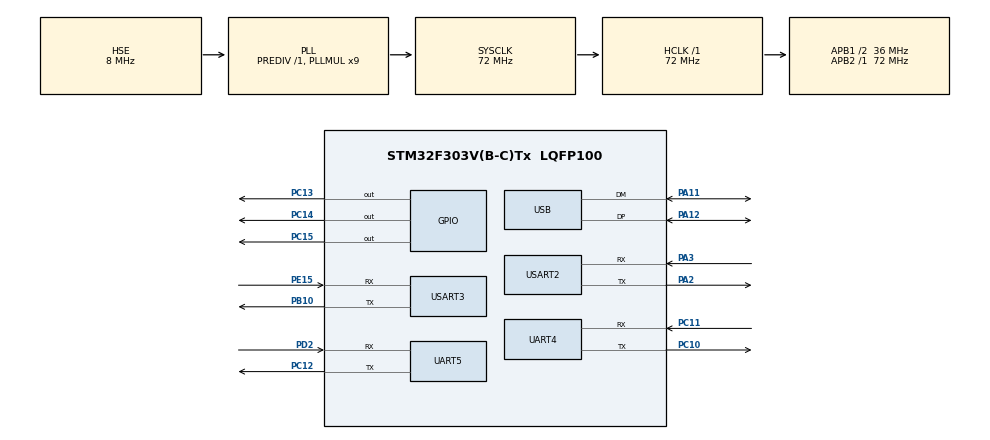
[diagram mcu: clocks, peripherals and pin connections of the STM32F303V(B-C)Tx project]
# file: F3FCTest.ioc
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Mcu.Family=STM32F3
Mcu.Name=STM32F303V(B-C)Tx
Mcu.Package=LQFP100
NVIC.PriorityGroup=NVIC_PRIORITYGROUP_4
PA11.Mode=Device
PA11.Signal=USB_DM
PA12.Mode=Device
PA12.Signal=USB_DP
PA13.Mode=Serial-Wire
PA13.Signal=SYS_JTMS-SWDIO
PA14.Mode=Serial-Wire
PA14.Signal=SYS_JTCK-SWCLK
PA2.Mode=Asynchronous
PA2.Signal=USART2_TX
PA3.Mode=Asynchronous
PA3.Signal=USART2_RX
PB10.Mode=Asynchronous
PB10.Signal=USART3_TX
PC10.Mode=Asynchronous
PC10.Signal=UART4_TX
PC11.Mode=Asynchronous
PC11.Signal=UART4_RX
PC12.Mode=Asynchronous
PC12.Signal=UART5_TX
PC13.Signal=GPIO_Output
PC14-OSC32_IN.Signal=GPIO_Output
PC15-OSC32_OUT.Signal=GPIO_Output
PD2.Mode=Asynchronous
PD2.Signal=UART5_RX
PE15.Mode=Asynchronous
PE15.Signal=USART3_RX
PF0-OSC_IN.Mode=HSE-External-Oscillator
PF0-OSC_IN.Signal=RCC_OSC_IN
PF1-OSC_OUT.Mode=HSE-External-Oscillator
PF1-OSC_OUT.Signal=RCC_OSC_OUT
ProjectManager.TargetToolchain=SW4STM32
RCC.AHBFreq_Value=72000000
RCC.APB1CLKDivider=RCC_HCLK_DIV2
RCC.APB1Freq_Value=36000000
RCC.APB1TimFreq_Value=72000000
RCC.APB2Freq_Value=72000000
RCC.APB2TimFreq_Value=72000000
RCC.CortexFreq_Value=72000000
RCC.HCLKFreq_Value=72000000
RCC.HSE_VALUE=8000000
RCC.HSIState=RCC_HSI_ON
RCC.HSI_VALUE=8000000
RCC.LSE_VALUE=32768
RCC.PLLMUL=RCC_PLL_MUL9
RCC.PRESCALERUSB=RCC_USBPLLCLK_DIV1_5
RCC.SYSCLKFreq_VALUE=72000000
RCC.SYSCLKSourceVirtual=RCC_SYSCLKSOURCE_PLLCLK
RCC.USBFreq_Value=48000000
board=F3FCTest

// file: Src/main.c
/**
  ******************************************************************************
  * File Name          : main.c
  * Description        : Main program body
  ******************************************************************************
  *
  * COPYRIGHT(c) 2015 STMicroelectronics
  *
  * Redistribution and use in source and binary forms, with or without modification,
  * are permitted provided that the following conditions are met:
  *   1. Redistributions of source code must retain the above copyright notice,
  *      this list of conditions and the following disclaimer.
  *   2. Redistributions in binary form must reproduce the above copyright notice,
  *      this list of conditions and the following disclaimer in the documentation
  *      and/or other materials provided with the distribution.
  *   3. Neither the name of STMicroelectronics nor the names of its contributors
  *      may be used to endorse or promote products derived from this software
  *      without specific prior written permission.
  *
  * THIS SOFTWARE IS PROVIDED BY THE COPYRIGHT HOLDERS AND CONTRIBUTORS "AS IS"
  * AND ANY EXPRESS OR IMPLIED WARRANTIES, INCLUDING, BUT NOT LIMITED TO, THE
  * IMPLIED WARRANTIES OF MERCHANTABILITY AND FITNESS FOR A PARTICULAR PURPOSE ARE
  * DISCLAIMED. IN NO EVENT SHALL THE COPYRIGHT HOLDER OR CONTRIBUTORS BE LIABLE
  * FOR ANY DIRECT, INDIRECT, INCIDENTAL, SPECIAL, EXEMPLARY, OR CONSEQUENTIAL
  * DAMAGES (INCLUDING, BUT NOT LIMITED TO, PROCUREMENT OF SUBSTITUTE GOODS OR
  * SERVICES; LOSS OF USE, DATA, OR PROFITS; OR BUSINESS INTERRUPTION) HOWEVER
  * CAUSED AND ON ANY THEORY OF LIABILITY, WHETHER IN CONTRACT, STRICT LIABILITY,
  * OR TORT (INCLUDING NEGLIGENCE OR OTHERWISE) ARISING IN ANY WAY OUT OF THE USE
  * OF THIS SOFTWARE, EVEN IF ADVISED OF THE POSSIBILITY OF SUCH DAMAGE.
  *
  ******************************************************************************
  */
#include "stm32f3xx_hal.h"

UART_HandleTypeDef huart4;
UART_HandleTypeDef huart5;
UART_HandleTypeDef huart2;
UART_HandleTypeDef huart3;

PCD_HandleTypeDef hpcd_USB_FS;

/* USER CODE BEGIN PV */
/* Private variables ---------------------------------------------------------*/

/* USER CODE END PV */

void SystemClock_Config(void);
static void MX_GPIO_Init(void);
static void MX_UART4_Init(void);
static void MX_UART5_Init(void);
static void MX_USART2_UART_Init(void);
static void MX_USART3_UART_Init(void);
static void MX_USB_PCD_Init(void);

/* USER CODE BEGIN PFP */
/* Private function prototypes -----------------------------------------------*/

/* USER CODE END PFP */

int main(void)
{

  /* MCU Configuration----------------------------------------------------------*/

  /* Reset of all peripherals, Initializes the Flash interface and the Systick. */
  HAL_Init();

  /* Configure the system clock */
  SystemClock_Config();

  /* Initialize all configured peripherals */
  MX_GPIO_Init();
  MX_UART4_Init();
  MX_UART5_Init();
  MX_USART2_UART_Init();
  MX_USART3_UART_Init();
  MX_USB_PCD_Init();

  /* USER CODE BEGIN 2 */
  long i = 0;
  /* USER CODE END 2 */

  /* Infinite loop */
  /* USER CODE BEGIN WHILE */
  while (1)
  {
    HAL_GPIO_TogglePin(GPIOC, GPIO_PIN_13);
    HAL_GPIO_TogglePin(GPIOC, GPIO_PIN_14);
    HAL_GPIO_TogglePin(GPIOC, GPIO_PIN_15);
    for(i = 0; i < 50000; i++);
  /* USER CODE END WHILE */

  }

}

/** System Clock Configuration
*/
void SystemClock_Config(void)
{

  RCC_OscInitTypeDef RCC_OscInitStruct;
  RCC_ClkInitTypeDef RCC_ClkInitStruct;
  RCC_PeriphCLKInitTypeDef PeriphClkInit;

  RCC_OscInitStruct.OscillatorType = RCC_OSCILLATORTYPE_HSE;
  RCC_OscInitStruct.HSEState = RCC_HSE_ON;
  RCC_OscInitStruct.HSEPredivValue = RCC_HSE_PREDIV_DIV1;
  RCC_OscInitStruct.PLL.PLLState = RCC_PLL_ON;
  RCC_OscInitStruct.PLL.PLLSource = RCC_PLLSOURCE_HSE;
  RCC_OscInitStruct.PLL.PLLMUL = RCC_PLL_MUL9;
  HAL_RCC_OscConfig(&RCC_OscInitStruct);

  RCC_ClkInitStruct.ClockType = RCC_CLOCKTYPE_SYSCLK|RCC_CLOCKTYPE_PCLK1;
  RCC_ClkInitStruct.SYSCLKSource = RCC_SYSCLKSOURCE_PLLCLK;
  RCC_ClkInitStruct.AHBCLKDivider = RCC_SYSCLK_DIV1;
  RCC_ClkInitStruct.APB1CLKDivider = RCC_HCLK_DIV2;
  RCC_ClkInitStruct.APB2CLKDivider = RCC_HCLK_DIV1;
  HAL_RCC_ClockConfig(&RCC_ClkInitStruct, FLASH_LATENCY_2);

  PeriphClkInit.PeriphClockSelection = RCC_PERIPHCLK_USB|RCC_PERIPHCLK_USART2
                              |RCC_PERIPHCLK_USART3|RCC_PERIPHCLK_UART4
                              |RCC_PERIPHCLK_UART5;
  PeriphClkInit.Usart2ClockSelection = RCC_USART2CLKSOURCE_PCLK1;
  PeriphClkInit.Usart3ClockSelection = RCC_USART3CLKSOURCE_PCLK1;
  PeriphClkInit.Uart4ClockSelection = RCC_UART4CLKSOURCE_PCLK1;
  PeriphClkInit.Uart5ClockSelection = RCC_UART5CLKSOURCE_PCLK1;
  PeriphClkInit.USBClockSelection = RCC_USBPLLCLK_DIV1_5;
  HAL_RCCEx_PeriphCLKConfig(&PeriphClkInit);

  HAL_SYSTICK_Config(HAL_RCC_GetHCLKFreq()/1000);

  HAL_SYSTICK_CLKSourceConfig(SYSTICK_CLKSOURCE_HCLK);

  /* SysTick_IRQn interrupt configuration */
  HAL_NVIC_SetPriority(SysTick_IRQn, 0, 0);
}

/* UART4 init function */
void MX_UART4_Init(void)
{

  huart4.Instance = UART4;
  huart4.Init.BaudRate = 115200;
  huart4.Init.WordLength = UART_WORDLENGTH_8B;
  huart4.Init.StopBits = UART_STOPBITS_1;
  huart4.Init.Parity = UART_PARITY_NONE;
  huart4.Init.Mode = UART_MODE_TX_RX;
  huart4.Init.HwFlowCtl = UART_HWCONTROL_NONE;
  huart4.Init.OverSampling = UART_OVERSAMPLING_16;
  huart4.Init.OneBitSampling = UART_ONEBIT_SAMPLING_DISABLED ;
  huart4.AdvancedInit.AdvFeatureInit = UART_ADVFEATURE_NO_INIT;
  HAL_UART_Init(&huart4);

}

/* UART5 init function */
void MX_UART5_Init(void)
{

  huart5.Instance = UART5;
  huart5.Init.BaudRate = 115200;
  huart5.Init.WordLength = UART_WORDLENGTH_8B;
  huart5.Init.StopBits = UART_STOPBITS_1;
  huart5.Init.Parity = UART_PARITY_NONE;
  huart5.Init.Mode = UART_MODE_TX_RX;
  huart5.Init.HwFlowCtl = UART_HWCONTROL_NONE;
  huart5.Init.OverSampling = UART_OVERSAMPLING_16;
  huart5.Init.OneBitSampling = UART_ONEBIT_SAMPLING_DISABLED ;
  huart5.AdvancedInit.AdvFeatureInit = UART_ADVFEATURE_NO_INIT;
  HAL_UART_Init(&huart5);

}

/* USART2 init function */
void MX_USART2_UART_Init(void)
{

  huart2.Instance = USART2;
  huart2.Init.BaudRate = 38400;
  huart2.Init.WordLength = UART_WORDLENGTH_8B;
  huart2.Init.StopBits = UART_STOPBITS_1;
  huart2.Init.Parity = UART_PARITY_NONE;
  huart2.Init.Mode = UART_MODE_TX_RX;
  huart2.Init.HwFlowCtl = UART_HWCONTROL_NONE;
  huart2.Init.OverSampling = UART_OVERSAMPLING_16;
  huart2.Init.OneBitSampling = UART_ONEBIT_SAMPLING_DISABLED ;
  huart2.AdvancedInit.AdvFeatureInit = UART_ADVFEATURE_NO_INIT;
  HAL_UART_Init(&huart2);

}

/* USART3 init function */
void MX_USART3_UART_Init(void)
{

  huart3.Instance = USART3;
  huart3.Init.BaudRate = 38400;
  huart3.Init.WordLength = UART_WORDLENGTH_8B;
  huart3.Init.StopBits = UART_STOPBITS_1;
  huart3.Init.Parity = UART_PARITY_NONE;
  huart3.Init.Mode = UART_MODE_TX_RX;
  huart3.Init.HwFlowCtl = UART_HWCONTROL_NONE;
  huart3.Init.OverSampling = UART_OVERSAMPLING_16;
  huart3.Init.OneBitSampling = UART_ONEBIT_SAMPLING_DISABLED ;
  huart3.AdvancedInit.AdvFeatureInit = UART_ADVFEATURE_NO_INIT;
  HAL_UART_Init(&huart3);

}

/* USB init function */
void MX_USB_PCD_Init(void)
{

  hpcd_USB_FS.Instance = USB;
  hpcd_USB_FS.Init.dev_endpoints = 8;
  hpcd_USB_FS.Init.speed = PCD_SPEED_FULL;
  hpcd_USB_FS.Init.ep0_mps = DEP0CTL_MPS_64;
  hpcd_USB_FS.Init.phy_itface = PCD_PHY_EMBEDDED;
  hpcd_USB_FS.Init.low_power_enable = DISABLE;
  hpcd_USB_FS.Init.battery_charging_enable = DISABLE;
  HAL_PCD_Init(&hpcd_USB_FS);

}

/** Configure pins as
        * Analog
        * Input
        * Output
        * EVENT_OUT
        * EXTI
*/
void MX_GPIO_Init(void)
{

  /* GPIO Ports Clock Enable */
  __GPIOF_CLK_ENABLE();
  __GPIOA_CLK_ENABLE();
  __GPIOE_CLK_ENABLE();
  __GPIOB_CLK_ENABLE();
  __GPIOC_CLK_ENABLE();
  __GPIOD_CLK_ENABLE();

}

/************************ (C) COPYRIGHT STMicroelectronics *****END OF FILE****/
